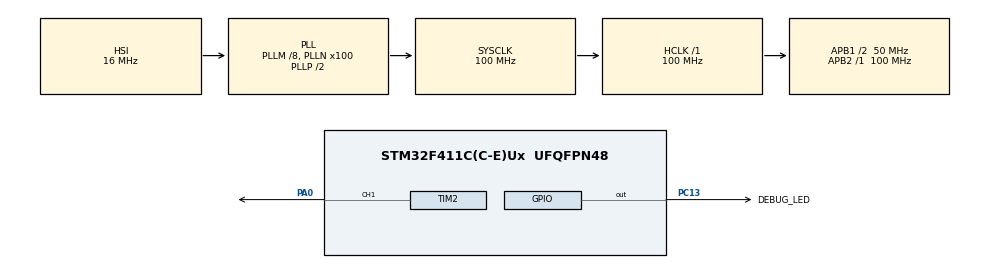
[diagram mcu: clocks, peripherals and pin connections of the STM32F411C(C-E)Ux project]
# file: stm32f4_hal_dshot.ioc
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Dma.Request0=TIM2_CH1
Dma.TIM2_CH1.0.Direction=DMA_MEMORY_TO_PERIPH
Dma.TIM2_CH1.0.FIFOMode=DMA_FIFOMODE_ENABLE
Dma.TIM2_CH1.0.FIFOThreshold=DMA_FIFO_THRESHOLD_1QUARTERFULL
Dma.TIM2_CH1.0.Instance=DMA1_Stream5
Dma.TIM2_CH1.0.MemBurst=DMA_MBURST_SINGLE
Dma.TIM2_CH1.0.MemDataAlignment=DMA_MDATAALIGN_WORD
Dma.TIM2_CH1.0.MemInc=DMA_MINC_ENABLE
Dma.TIM2_CH1.0.Mode=DMA_NORMAL
Dma.TIM2_CH1.0.PeriphBurst=DMA_PBURST_SINGLE
Dma.TIM2_CH1.0.PeriphDataAlignment=DMA_PDATAALIGN_WORD
Dma.TIM2_CH1.0.PeriphInc=DMA_PINC_DISABLE
Dma.TIM2_CH1.0.Priority=DMA_PRIORITY_LOW
Mcu.Family=STM32F4
Mcu.Name=STM32F411C(C-E)Ux
Mcu.Package=UFQFPN48
NVIC.DMA1_Stream5_IRQn=true\:0\:0\:false\:false\:true\:false\:true
NVIC.PriorityGroup=NVIC_PRIORITYGROUP_4
NVIC.TIM1_TRG_COM_TIM11_IRQn=true\:0\:0\:false\:false\:true\:true\:true
PA0-WKUP.Signal=S_TIM2_CH1_ETR
PA13.Mode=Serial_Wire
PA13.Signal=SYS_JTMS-SWDIO
PA14.Mode=Serial_Wire
PA14.Signal=SYS_JTCK-SWCLK
PC13-ANTI_TAMP.GPIO_Label=DEBUG_LED
PC13-ANTI_TAMP.PinState=GPIO_PIN_SET
PC13-ANTI_TAMP.Signal=GPIO_Output
PC14-OSC32_IN.Mode=LSE-External-Oscillator
PC14-OSC32_IN.Signal=RCC_OSC32_IN
PC15-OSC32_OUT.Mode=LSE-External-Oscillator
PC15-OSC32_OUT.Signal=RCC_OSC32_OUT
PH0\ -\ OSC_IN.Mode=HSE-External-Oscillator
PH0\ -\ OSC_IN.Signal=RCC_OSC_IN
PH1\ -\ OSC_OUT.Mode=HSE-External-Oscillator
PH1\ -\ OSC_OUT.Signal=RCC_OSC_OUT
ProjectManager.HeapSize=0x200
ProjectManager.StackSize=0x400
ProjectManager.TargetToolchain=STM32CubeIDE
RCC.48MHZClocksFreq_Value=50000000
RCC.AHBFreq_Value=100000000
RCC.APB1CLKDivider=RCC_HCLK_DIV2
RCC.APB1Freq_Value=50000000
RCC.APB1TimFreq_Value=100000000
RCC.APB2Freq_Value=100000000
RCC.APB2TimFreq_Value=100000000
RCC.CortexFreq_Value=100000000
RCC.HCLKFreq_Value=100000000
RCC.HSE_VALUE=25000000
RCC.HSI_VALUE=16000000
RCC.PLLM=8
RCC.PLLN=100
RCC.SYSCLKFreq_VALUE=100000000
RCC.SYSCLKSource=RCC_SYSCLKSOURCE_PLLCLK
RCC.VCOOutputFreq_Value=200000000
SH.S_TIM2_CH1_ETR.0=TIM2_CH1,PWM Generation1 CH1
TIM11.Period=9
TIM11.Prescaler=9999
TIM2.Channel-PWM\ Generation1\ CH1=TIM_CHANNEL_1
TIM2.Period=20-1
TIM2.Prescaler=8-1
TIM2.Pulse-PWM\ Generation1\ CH1=0
VP_TIM11_VS_ClockSourceINT.Mode=Enable_Timer
board=custom

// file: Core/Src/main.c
/* USER CODE BEGIN Header */
/**
  ******************************************************************************
  * @file           : main.c
  * @brief          : Main program body
  ******************************************************************************
  * @attention
  *
  * <h2><center>&copy; Copyright (c) 2021 STMicroelectronics.
  * All rights reserved.</center></h2>
  *
  * This software component is licensed by ST under BSD 3-Clause license,
  * the "License"; You may not use this file except in compliance with the
  * License. You may obtain a copy of the License at:
  *                        opensource.org/licenses/BSD-3-Clause
  *
  ******************************************************************************
  */
/* USER CODE END Header */
#include "main.h"
#include "dma.h"
#include "tim.h"
#include "gpio.h"

/* USER CODE BEGIN Includes */

#include "dshot.h"
/* USER CODE END Includes */

/* USER CODE BEGIN PV */

uint32_t motor1[DSHOT_FRAME_SIZE];
uint16_t value = 0;					// need to keep value = 0 for a while after power on

/* USER CODE END PV */

void SystemClock_Config(void);

/* USER CODE BEGIN 0 */

void HAL_TIM_PeriodElapsedCallback(TIM_HandleTypeDef *htim)
{
  if (htim == &htim11)
  {
	  dshot600(motor1, value);
	  HAL_TIM_PWM_Start_DMA(&htim2, TIM_CHANNEL_1, motor1, 18);
  }
}

/* USER CODE END 0 */

int main(void)
{

  /* MCU Configuration--------------------------------------------------------*/

  /* Reset of all peripherals, Initializes the Flash interface and the Systick. */
    HAL_Init();

  /* Configure the system clock */
  SystemClock_Config();

  /* Initialize all configured peripherals */
  MX_GPIO_Init();
  MX_DMA_Init();
  MX_TIM2_Init();
  MX_TIM11_Init();
  /* USER CODE BEGIN 2 */

  HAL_TIM_Base_Start_IT(&htim11); // timer interrupt 1kHz

  /* USER CODE END 2 */

  /* Infinite loop */
  while (1)
  {

  }
}

void SystemClock_Config(void)
{
  RCC_OscInitTypeDef RCC_OscInitStruct = {0};
  RCC_ClkInitTypeDef RCC_ClkInitStruct = {0};

  /** Configure the main internal regulator output voltage
  */
  __HAL_RCC_PWR_CLK_ENABLE();
  __HAL_PWR_VOLTAGESCALING_CONFIG(PWR_REGULATOR_VOLTAGE_SCALE1);
  /** Initializes the RCC Oscillators according to the specified parameters
  * in the RCC_OscInitTypeDef structure.
  */
  RCC_OscInitStruct.OscillatorType = RCC_OSCILLATORTYPE_HSI;
  RCC_OscInitStruct.HSIState = RCC_HSI_ON;
  RCC_OscInitStruct.HSICalibrationValue = RCC_HSICALIBRATION_DEFAULT;
  RCC_OscInitStruct.PLL.PLLState = RCC_PLL_ON;
  RCC_OscInitStruct.PLL.PLLSource = RCC_PLLSOURCE_HSI;
  RCC_OscInitStruct.PLL.PLLM = 8;
  RCC_OscInitStruct.PLL.PLLN = 100;
  RCC_OscInitStruct.PLL.PLLP = RCC_PLLP_DIV2;
  RCC_OscInitStruct.PLL.PLLQ = 4;
  if (HAL_RCC_OscConfig(&RCC_OscInitStruct) != HAL_OK)
  {
    Error_Handler();
  }
  /** Initializes the CPU, AHB and APB buses clocks
  */
  RCC_ClkInitStruct.ClockType = RCC_CLOCKTYPE_HCLK|RCC_CLOCKTYPE_SYSCLK
                              |RCC_CLOCKTYPE_PCLK1|RCC_CLOCKTYPE_PCLK2;
  RCC_ClkInitStruct.SYSCLKSource = RCC_SYSCLKSOURCE_PLLCLK;
  RCC_ClkInitStruct.AHBCLKDivider = RCC_SYSCLK_DIV1;
  RCC_ClkInitStruct.APB1CLKDivider = RCC_HCLK_DIV2;
  RCC_ClkInitStruct.APB2CLKDivider = RCC_HCLK_DIV1;

  if (HAL_RCC_ClockConfig(&RCC_ClkInitStruct, FLASH_LATENCY_3) != HAL_OK)
  {
    Error_Handler();
  }
}

void Error_Handler(void)
{
  __disable_irq();
  while (1)
  {
  }
}

/************************ (C) COPYRIGHT STMicroelectronics *****END OF FILE****/
